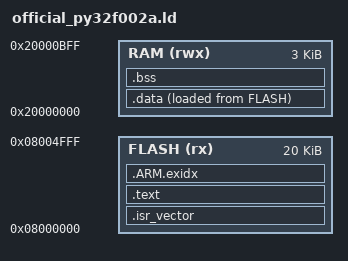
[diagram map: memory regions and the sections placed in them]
ENTRY(Reset_Handler)
_estack = ORIGIN(RAM) + LENGTH(RAM);

MEMORY
{
    FLASH (rx)  : ORIGIN = 0x08000000, LENGTH = 20K
    RAM   (rwx) : ORIGIN = 0x20000000, LENGTH = 3K
}

SECTIONS
{
    .isr_vector : { KEEP(*(.isr_vector)) } > FLASH
    .text : { *(.text*) *(.rodata*) } > FLASH
    .ARM.exidx : { *(.ARM.exidx*) } > FLASH
    _sidata = LOADADDR(.data);
    .data : { _sdata = .; *(.data*) _edata = .; } > RAM AT > FLASH
    .bss (NOLOAD) : { _sbss = .; *(.bss*) *(COMMON) _ebss = .; } > RAM
}

